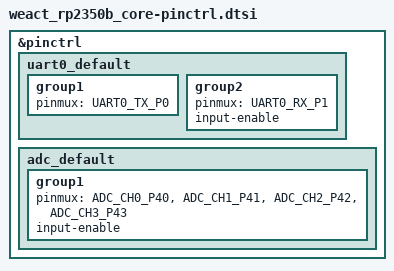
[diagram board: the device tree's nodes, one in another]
/*
 * Copyright (c) 2026 Ekorau LLC
 * SPDX-License-Identifier: Apache-2.0
 *
 * Only what this board port claims: uart0 on GP0/GP1 (the console pair every RP2 port here
 * shares, so one adapter wiring and one collector env file serve them all) and the four
 * ADC inputs on GP40–43. The other 44 GPIO are left to the application's overlay.
 */
#include <zephyr/dt-bindings/pinctrl/rpi-pico-rp2350b-pinctrl.h>

&pinctrl {
	uart0_default: uart0_default {
		group1 {
			pinmux = <UART0_TX_P0>;
		};
		group2 {
			pinmux = <UART0_RX_P1>;
			input-enable;
		};
	};

	adc_default: adc_default {
		group1 {
			pinmux = <ADC_CH0_P40>, <ADC_CH1_P41>, <ADC_CH2_P42>, <ADC_CH3_P43>;
			input-enable;
		};
	};
};
